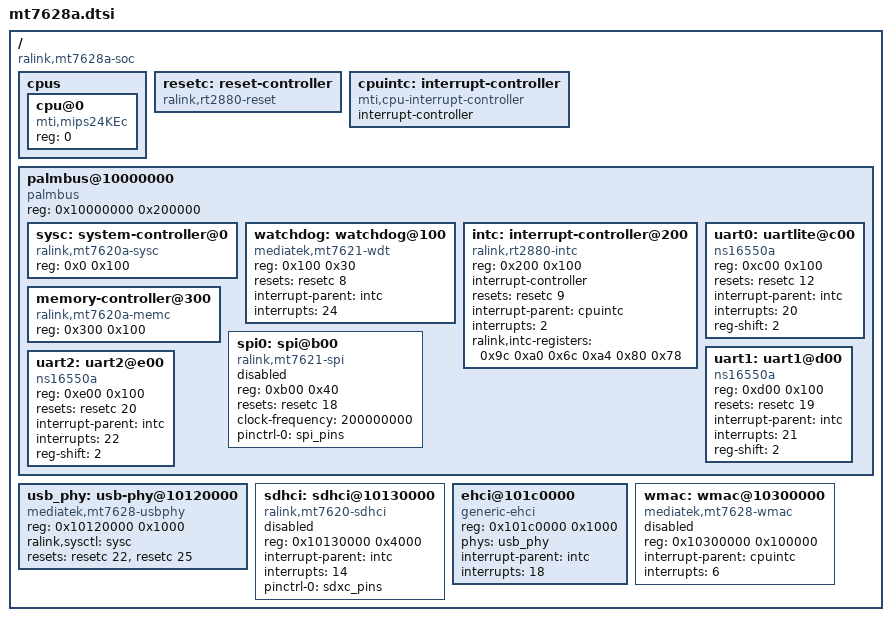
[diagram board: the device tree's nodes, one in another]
/ {
	#address-cells = <1>;
	#size-cells = <1>;
	compatible = "ralink,mt7628a-soc";

	cpus {
		#address-cells = <1>;
		#size-cells = <0>;

		cpu@0 {
			compatible = "mti,mips24KEc";
			device_type = "cpu";
			reg = <0>;
		};
	};

	resetc: reset-controller {
		compatible = "ralink,rt2880-reset";
		#reset-cells = <1>;
	};

	cpuintc: interrupt-controller {
		#address-cells = <0>;
		#interrupt-cells = <1>;
		interrupt-controller;
		compatible = "mti,cpu-interrupt-controller";
	};

	palmbus@10000000 {
		compatible = "palmbus";
		reg = <0x10000000 0x200000>;
		ranges = <0x0 0x10000000 0x1FFFFF>;

		#address-cells = <1>;
		#size-cells = <1>;

		sysc: system-controller@0 {
			compatible = "ralink,mt7620a-sysc", "syscon";
			reg = <0x0 0x100>;
		};

		watchdog: watchdog@100 {
			compatible = "mediatek,mt7621-wdt";
			reg = <0x100 0x30>;

			resets = <&resetc 8>;
			reset-names = "wdt";

			interrupt-parent = <&intc>;
			interrupts = <24>;
		};

		intc: interrupt-controller@200 {
			compatible = "ralink,rt2880-intc";
			reg = <0x200 0x100>;

			interrupt-controller;
			#interrupt-cells = <1>;

			resets = <&resetc 9>;
			reset-names = "intc";

			interrupt-parent = <&cpuintc>;
			interrupts = <2>;

			ralink,intc-registers = <0x9c 0xa0
						 0x6c 0xa4
						 0x80 0x78>;
		};

		memory-controller@300 {
			compatible = "ralink,mt7620a-memc";
			reg = <0x300 0x100>;
		};

		spi0: spi@b00 {
			compatible = "ralink,mt7621-spi";
			reg = <0xb00 0x40>;
			#address-cells = <1>;
			#size-cells = <0>;

			resets = <&resetc 18>;
			reset-names = "spi";

			clock-frequency = <200000000>;

			pinctrl-names = "default";
			pinctrl-0 = <&spi_pins>;

			status = "disabled";
		};

		uart0: uartlite@c00 {
			compatible = "ns16550a";
			reg = <0xc00 0x100>;

			resets = <&resetc 12>;
			reset-names = "uart0";

			interrupt-parent = <&intc>;
			interrupts = <20>;

			reg-shift = <2>;
		};

		uart1: uart1@d00 {
			compatible = "ns16550a";
			reg = <0xd00 0x100>;

			resets = <&resetc 19>;
			reset-names = "uart1";

			interrupt-parent = <&intc>;
			interrupts = <21>;

			reg-shift = <2>;
		};

		uart2: uart2@e00 {
			compatible = "ns16550a";
			reg = <0xe00 0x100>;

			resets = <&resetc 20>;
			reset-names = "uart2";

			interrupt-parent = <&intc>;
			interrupts = <22>;

			reg-shift = <2>;
		};
	};

	usb_phy: usb-phy@10120000 {
		compatible = "mediatek,mt7628-usbphy";
		reg = <0x10120000 0x1000>;

		#phy-cells = <0>;

		ralink,sysctl = <&sysc>;
		resets = <&resetc 22 &resetc 25>;
		reset-names = "host", "device";
	};

	sdhci: sdhci@10130000 {
		compatible = "ralink,mt7620-sdhci";
		reg = <0x10130000 0x4000>;

		interrupt-parent = <&intc>;
		interrupts = <14>;

		pinctrl-names = "default";
		pinctrl-0 = <&sdxc_pins>;

		status = "disabled";
	};

	ehci@101c0000 {
		compatible = "generic-ehci";
		reg = <0x101c0000 0x1000>;

		phys = <&usb_phy>;
		phy-names = "usb";

		interrupt-parent = <&intc>;
		interrupts = <18>;
	};

	wmac: wmac@10300000 {
		compatible = "mediatek,mt7628-wmac";
		reg = <0x10300000 0x100000>;

		interrupt-parent = <&cpuintc>;
		interrupts = <6>;

		status = "disabled";
	};
};
